# STNRG328A register map
Vendor: STMicroelectronics; Series: STNRG; File version: 1.0
CPU: other r1p0, big endian, no MPU, no FPU, 4 interrupt priority bits
Registers are 8-bit, read-write, reset 0x0 unless marked. A register's access mark holds for its fields unless they carry their own. Offsets are from the block's base; [hi:lo] are bit positions; {n}, {i} and the like mark numbered series.

## DALI
Base 0x000053C0
0x00 DALI_L — Clock prescaler LSB
  [7:0] DALI_CLK
0x01 DALI_H — Clock prescaler MSB
  [1:0] DALI_CLK
{0x2+i} DALI_FB{i} (i=0..2) — Message byte {i} register
0x05 DALI_BD — Backward Data register
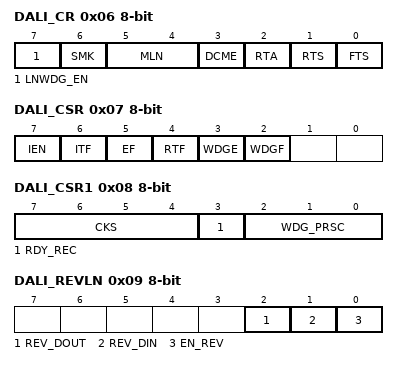
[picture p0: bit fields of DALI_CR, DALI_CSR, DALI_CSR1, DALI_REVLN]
0x06 DALI_CR — Control register
  [7] LNWDG_EN, [6] SMK, [5:4] MLN, [3] DCME, [2] RTA, [1] RTS, [0] FTS
0x07 DALI_CSR — Control and Status register
  [7] IEN, [6] ITF, [5] EF, [4] RTF, [3] WDGE, [2] WDGF
0x08 DALI_CSR1 — Control and Status register1
  [7:4] CKS, [3] RDY_REC, [2:0] WDG_PRSC
0x09 DALI_REVLN — Control reverse signal line
  [2] REV_DOUT, [1] REV_DIN, [0] EN_REV

## FLASH
Base 0x0000505A
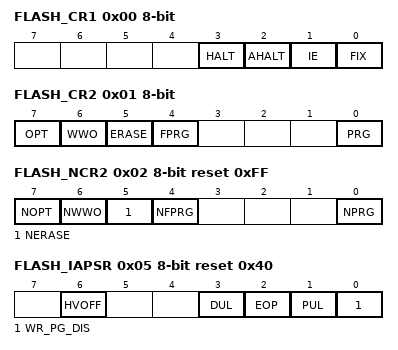
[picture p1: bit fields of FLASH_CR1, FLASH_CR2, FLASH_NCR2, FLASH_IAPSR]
0x00 FLASH_CR1 — Flash control register 1
  [3] HALT, [2] AHALT, [1] IE, [0] FIX
0x01 FLASH_CR2 — Flash control register 2
  [7] OPT, [6] WWO, [5] ERASE, [4] FPRG, [0] PRG
0x02 FLASH_NCR2 reset 0xFF — Flash complementary control register 2
  [7] NOPT, [6] NWWO, [5] NERASE, [4] NFPRG, [0] NPRG
0x03 FLASH_FPR — Flash protection register
  [7:0] WPB
0x04 FLASH_NFPR reset 0xFF — Flash complementary protection register
  [7:0] NWPB
0x05 FLASH_IAPSR reset 0x40 — Flash status register
  [6] HVOFF, [3] DUL, [2] EOP, [1] PUL, [0] WR_PG_DIS
0x08 FLASH_PUKR — Flash program memory unprotection register
  [7:0] WP
0x0A FLASH_DUKR — Flash data unprotection register
  [7:0] WD
0x0D FLASH_WAIT — Flash wait state register
  [1:0] Wait

## I2C
Base 0x00005210
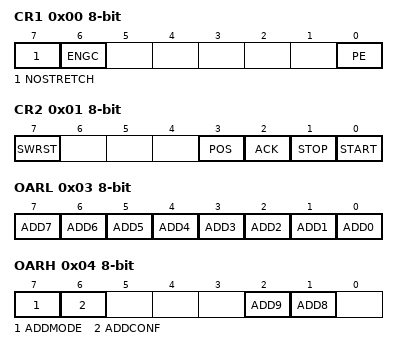
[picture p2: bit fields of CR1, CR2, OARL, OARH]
0x00 CR1 — I2C control register 1
  [7] NOSTRETCH, [6] ENGC, [0] PE
0x01 CR2 — I2C control register 2
  [7] SWRST, [3] POS, [2] ACK, [1] STOP, [0] START
0x02 FREQR — I2C frequency register
  [5:0] FREQ
0x03 OARL — I2C own address register low
  [n] ADD{n} (n=0..7)
0x04 OARH — I2C own address register high
  [7] ADDMODE, [6] ADDCONF, [2] ADD9, [1] ADD8
0x06 DR — I2C data register
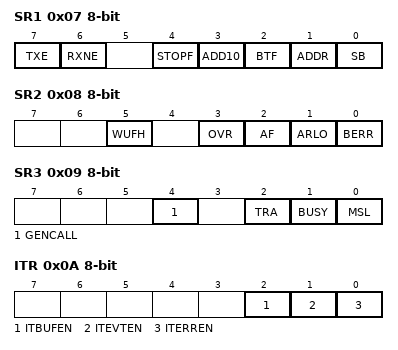
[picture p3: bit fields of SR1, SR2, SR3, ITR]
0x07 SR1 — I2C status register 1
  [7] TXE, [6] RXNE, [4] STOPF, [3] ADD10, [2] BTF, [1] ADDR, [0] SB
0x08 SR2 — I2C status register 2
  [5] WUFH, [3] OVR, [2] AF, [1] ARLO, [0] BERR
0x09 SR3 — I2C status register 3
  [4] GENCALL, [2] TRA, [1] BUSY, [0] MSL
0x0A ITR — I2C interrupt control register
  [2] ITBUFEN, [1] ITEVTEN, [0] ITERREN
0x0B CCRL — I2C clock control register low
  [7:0] CCR
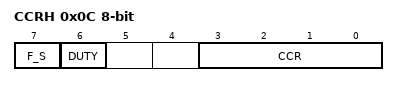
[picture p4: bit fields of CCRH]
0x0C CCRH — I2C clock control register high
  [7] F_S, [6] DUTY, [3:0] CCR
0x0D TRISER reset 0x2 — I2C TRISE register
  [5:0] TRISE

## ITC
Base 0x00007F70
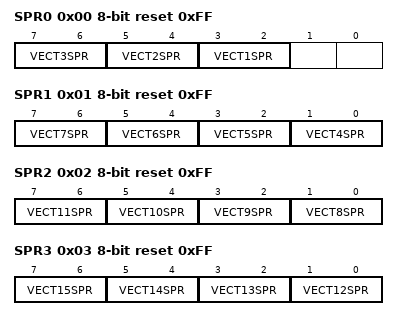
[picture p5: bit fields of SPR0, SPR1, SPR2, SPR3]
0x00 SPR0 reset 0xFF — Interrupt software priority register 0
  [7:6] VECT3SPR, [5:4] VECT2SPR, [3:2] VECT1SPR
0x01 SPR1 reset 0xFF — Interrupt software priority register 1
  [2n-7:2n-8] VECT{n}SPR (n=4..7)
0x02 SPR2 reset 0xFF — Interrupt software priority register 2
  [2n-15:2n-16] VECT{n}SPR (n=8..11)
0x03 SPR3 reset 0xFF — Interrupt software priority register 3
  [2n-23:2n-24] VECT{n}SPR (n=12..15)
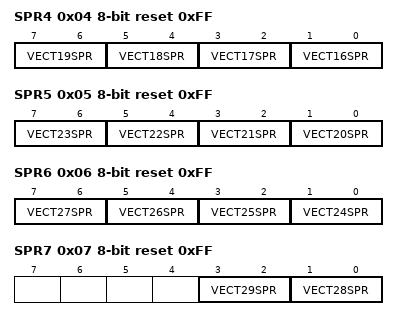
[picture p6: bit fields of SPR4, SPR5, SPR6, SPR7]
0x04 SPR4 reset 0xFF — Interrupt software priority register 4
  [2n-31:2n-32] VECT{n}SPR (n=16..19)
0x05 SPR5 reset 0xFF — Interrupt software priority register 5
  [2n-39:2n-40] VECT{n}SPR (n=20..23)
0x06 SPR6 reset 0xFF — Interrupt software priority register 6
  [2n-47:2n-48] VECT{n}SPR (n=24..27)
0x07 SPR7 reset 0xFF — Interrupt software priority register 7
  [3:2] VECT29SPR, [1:0] VECT28SPR

## MSC
Base 0x00005010
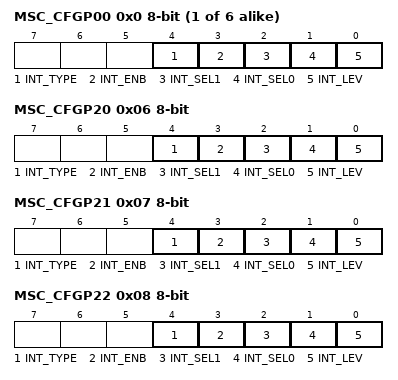
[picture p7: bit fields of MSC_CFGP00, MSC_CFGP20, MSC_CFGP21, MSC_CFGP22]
{0x0+i} MSC_CFGP{i:02} (i=0..5) — Control register for P0-{i} input line
  [4] INT_TYPE, [3] INT_ENB, [2] INT_SEL1, [1] INT_SEL0, [0] INT_LEV
0x06 MSC_CFGP20 — Control register for P2-0 input line
  [4] INT_TYPE, [3] INT_ENB, [2] INT_SEL1, [1] INT_SEL0, [0] INT_LEV
0x07 MSC_CFGP21 — Control register for P2-1 input line
  [4] INT_TYPE, [3] INT_ENB, [2] INT_SEL1, [1] INT_SEL0, [0] INT_LEV
0x08 MSC_CFGP22 — Control register for P2-2 input line
  [4] INT_TYPE, [3] INT_ENB, [2] INT_SEL1, [1] INT_SEL0, [0] INT_LEV
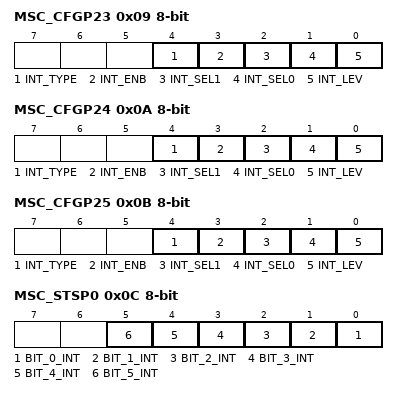
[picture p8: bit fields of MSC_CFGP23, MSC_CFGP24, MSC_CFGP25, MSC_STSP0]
0x09 MSC_CFGP23 — Control register for P2-3 input line
  [4] INT_TYPE, [3] INT_ENB, [2] INT_SEL1, [1] INT_SEL0, [0] INT_LEV
0x0A MSC_CFGP24 — Control register for P2-4 input line
  [4] INT_TYPE, [3] INT_ENB, [2] INT_SEL1, [1] INT_SEL0, [0] INT_LEV
0x0B MSC_CFGP25 — Control register for P2-5 input line
  [4] INT_TYPE, [3] INT_ENB, [2] INT_SEL1, [1] INT_SEL0, [0] INT_LEV
0x0C MSC_STSP0 — Port 0 Status register
  [n] BIT_{n}_INT (n=0..5)
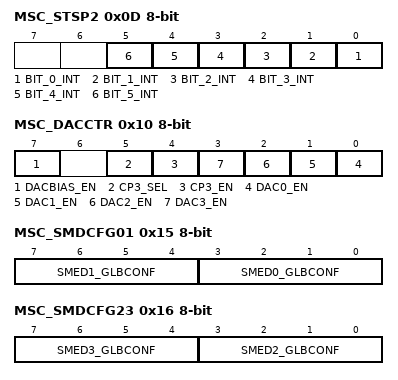
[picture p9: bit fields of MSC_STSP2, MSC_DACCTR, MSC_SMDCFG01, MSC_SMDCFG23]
0x0D MSC_STSP2 — Port 2 Status register
  [n] BIT_{n}_INT (n=0..5)
0x0E MSC_INPP2 — Port 2 inputs read register
  [5:0] DATA_IN
0x10 MSC_DACCTR — Enable DACs
  [7] DACBIAS_EN, [5] CP3_SEL, [4] CP3_EN, [n] DAC{n}_EN (n=0..3)
{0x11+i} MSC_DACIN{i} (i=0..3) — Four bit input value for DAC {i}
  [3:0] DAC_IN{i}
0x15 MSC_SMDCFG01 — SMED0,1 global configuration reg
  [7:4] SMED1_GLBCONF, [3:0] SMED0_GLBCONF
0x16 MSC_SMDCFG23 — SMED2,3 global configuration reg
  [7:4] SMED3_GLBCONF, [3:0] SMED2_GLBCONF
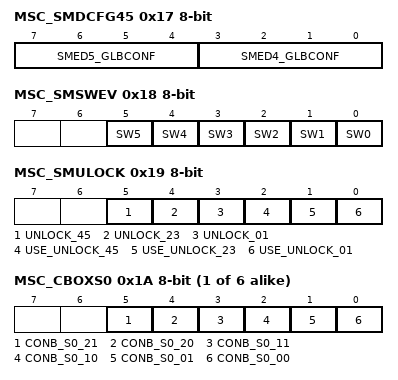
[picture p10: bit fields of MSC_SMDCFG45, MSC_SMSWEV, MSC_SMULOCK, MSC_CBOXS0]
0x17 MSC_SMDCFG45 — SMED4,5 global configuration reg
  [7:4] SMED5_GLBCONF, [3:0] SMED4_GLBCONF
0x18 MSC_SMSWEV — Software events for all SMED
  [n] SW{n} (n=0..5)
0x19 MSC_SMULOCK — Unlock controls for SMED
  [5] UNLOCK_45, [4] UNLOCK_23, [3] UNLOCK_01, [2] USE_UNLOCK_45, [1] USE_UNLOCK_23, [0] USE_UNLOCK_01
{0x1A+i} MSC_CBOXS{i} (i=0..5) — Connect Box selection for SMED{i}
  [5] CONB_S{i}_21, [4] CONB_S{i}_20, [3] CONB_S{i}_11, [2] CONB_S{i}_10, [1] CONB_S{i}_01, [0] CONB_S{i}_00
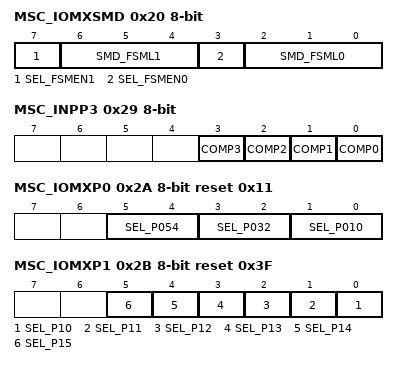
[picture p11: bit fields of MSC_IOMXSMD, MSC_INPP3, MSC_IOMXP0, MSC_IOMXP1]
0x20 MSC_IOMXSMD — I/O mux Port0 P0 SMED FSM state
  [7] SEL_FSMEN1, [6:4] SMD_FSML1, [3] SEL_FSMEN0, [2:0] SMD_FSML0
0x26 MSC_CFGP15 — Control register for AUXTIM input line
0x27 MSC_STSP1 — AUXTIM status register
0x29 MSC_INPP3 — Port 3 inputs read register
  [n] COMP{n} (n=0..3)
0x2A MSC_IOMXP0 reset 0x11 — I/O mux Port0 (GPIO0s) signals
  [5:4] SEL_P054, [3:2] SEL_P032, [1:0] SEL_P010
0x2B MSC_IOMXP1 reset 0x3F — I/O mux Port1 (PWMs/GPIO1s) signals
  [n-10] SEL_P{n} (n=10..15)
0x2C MSC_IDXADD — Miscellaneous indirect address
0x2D MSC_IDXDAT — Miscellaneous indirect data
